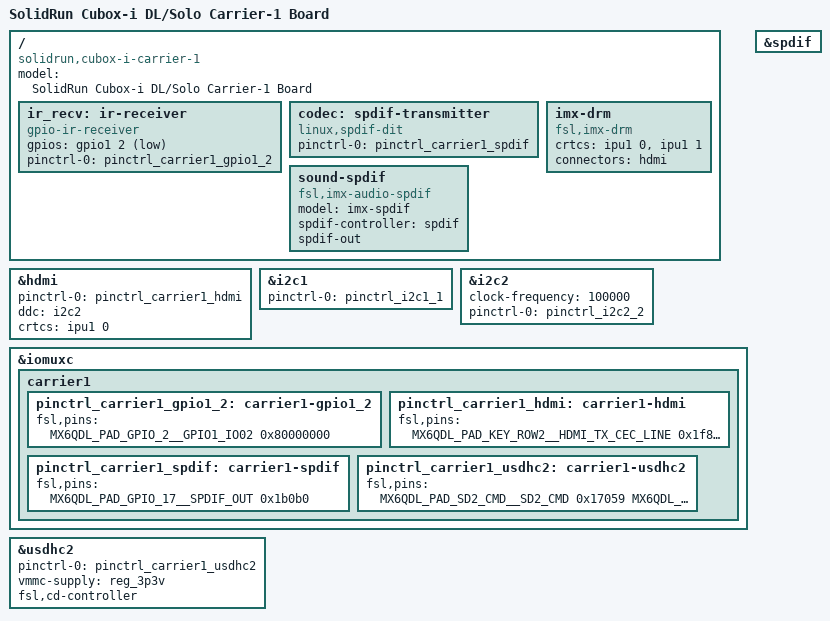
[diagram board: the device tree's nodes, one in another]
/*
 * Copyright (C) 2013 Russell King
 *
 * The code contained herein is licensed under the GNU General Public
 * License version 2.
 */
/dts-v1/;

#include "imx6dl.dtsi"
#include "imx6qdl-microsom.dtsi"
#include "imx6qdl-microsom-ar8035.dtsi"

/ {
	model = "SolidRun Cubox-i DL/Solo Carrier-1 Board";
	compatible = "solidrun,cubox-i-carrier-1", "fsl,imx6dl";

	ir_recv: ir-receiver {
		compatible = "gpio-ir-receiver";
		gpios = <&gpio1 2 1>;
		pinctrl-names = "default";
		pinctrl-0 = <&pinctrl_carrier1_gpio1_2>;
	};

	codec: spdif-transmitter {
		compatible = "linux,spdif-dit";
		pinctrl-names = "default";
		pinctrl-0 = <&pinctrl_carrier1_spdif>;
	};

	imx-drm {
		compatible = "fsl,imx-drm";
		crtcs = <&ipu1 0>, <&ipu1 1>;
		connectors = <&hdmi>;
	};

	sound-spdif {
		compatible = "fsl,imx-audio-spdif";
		model = "imx-spdif";
		/* IMX6 doesn't implement this yet */
		spdif-controller = <&spdif>;
		spdif-out;
	};
};

&hdmi {
	pinctrl-names = "default";
	pinctrl-0 = <&pinctrl_carrier1_hdmi>;
	ddc = <&i2c2>;
	status = "okay";
	crtcs = <&ipu1 0>;
};

&i2c1 {
	pinctrl-names = "default";
	pinctrl-0 = <&pinctrl_i2c1_1>;

	/*
	 * Not fitted on Carrier-1 board... yet
	status = "okay";

	rtc: pcf8523@68 {
		compatible = "nxp,pcf8523";
		reg = <0x68>;
	};
	 */
};

&i2c2 {
	clock-frequency = <100000>;
	pinctrl-names = "default";
	pinctrl-0 = <&pinctrl_i2c2_2>;
	status = "okay";
};

&iomuxc {
	carrier1 {
		pinctrl_carrier1_gpio1_2: carrier1-gpio1_2 {
			fsl,pins = <
				MX6QDL_PAD_GPIO_2__GPIO1_IO02 0x80000000
			>;
		};

		pinctrl_carrier1_hdmi: carrier1-hdmi {
			fsl,pins = <
				MX6QDL_PAD_KEY_ROW2__HDMI_TX_CEC_LINE 0x1f8b0
			>;
		};

		pinctrl_carrier1_spdif: carrier1-spdif {
			fsl,pins = <MX6QDL_PAD_GPIO_17__SPDIF_OUT 0x1b0b0>;
		};

		pinctrl_carrier1_usdhc2: carrier1-usdhc2 {
			fsl,pins = <
				MX6QDL_PAD_SD2_CMD__SD2_CMD    0x17059
				MX6QDL_PAD_SD2_CLK__SD2_CLK    0x10059
				MX6QDL_PAD_SD2_DAT0__SD2_DATA0 0x17059
				MX6QDL_PAD_SD2_DAT1__SD2_DATA1 0x17059
				MX6QDL_PAD_SD2_DAT2__SD2_DATA2 0x17059
				MX6QDL_PAD_SD2_DAT3__SD2_DATA3 0x13059
				MX6QDL_PAD_GPIO_4__SD2_CD_B    0x1f071
			>;
		};
	};
};

&spdif {
	status = "okay";
};

&usdhc2 {
	pinctrl-names = "default";
	pinctrl-0 = <&pinctrl_carrier1_usdhc2>;
	vmmc-supply = <&reg_3p3v>;
	fsl,cd-controller;
	status = "okay";
};
